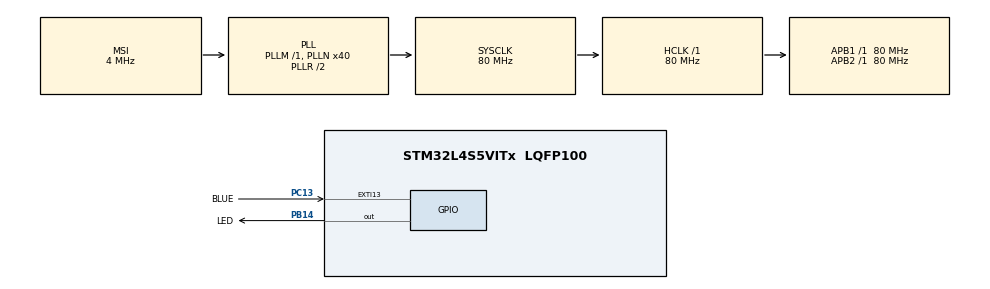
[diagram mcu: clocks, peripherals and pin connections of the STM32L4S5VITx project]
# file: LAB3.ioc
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ADC1.Channel-1\#ChannelRegularConversion=ADC_CHANNEL_TEMPSENSOR
ADC1.Channel-2\#ChannelRegularConversion=ADC_CHANNEL_VREFINT
ADC1.NbrOfConversion=2
ADC1.NbrOfConversionFlag=1
ADC1.OffsetNumber-1\#ChannelRegularConversion=ADC_OFFSET_NONE
ADC1.OffsetNumber-2\#ChannelRegularConversion=ADC_OFFSET_NONE
ADC1.Rank-1\#ChannelRegularConversion=1
ADC1.Rank-2\#ChannelRegularConversion=2
ADC1.Resolution=ADC_RESOLUTION_10B
ADC1.SamplingTime-1\#ChannelRegularConversion=ADC_SAMPLETIME_247CYCLES_5
ADC1.SamplingTime-2\#ChannelRegularConversion=ADC_SAMPLETIME_247CYCLES_5
ADC1.master=1
Dma.ADC1.0.Direction=DMA_PERIPH_TO_MEMORY
Dma.ADC1.0.EventEnable=DISABLE
Dma.ADC1.0.Instance=DMA1_Channel1
Dma.ADC1.0.MemDataAlignment=DMA_MDATAALIGN_HALFWORD
Dma.ADC1.0.MemInc=DMA_MINC_ENABLE
Dma.ADC1.0.Mode=DMA_NORMAL
Dma.ADC1.0.PeriphDataAlignment=DMA_PDATAALIGN_HALFWORD
Dma.ADC1.0.PeriphInc=DMA_PINC_DISABLE
Dma.ADC1.0.Polarity=HAL_DMAMUX_REQUEST_GEN_RISING
Dma.ADC1.0.Priority=DMA_PRIORITY_LOW
Dma.ADC1.0.RequestNumber=1
Dma.ADC1.0.SignalID=NONE
Dma.ADC1.0.SyncEnable=DISABLE
Dma.ADC1.0.SyncPolarity=HAL_DMAMUX_SYNC_NO_EVENT
Dma.ADC1.0.SyncRequestNumber=1
Dma.ADC1.0.SyncSignalID=NONE
Dma.Request0=ADC1
Mcu.Family=STM32L4
Mcu.Name=STM32L4S5VITx
Mcu.Package=LQFP100
NVIC.DMA1_Channel1_IRQn=true\:0\:0\:false\:false\:true\:false\:true\:true
NVIC.EXTI15_10_IRQn=true\:0\:0\:false\:false\:true\:true\:true\:true
NVIC.PriorityGroup=NVIC_PRIORITYGROUP_4
PA13\ (JTMS/SWDIO).Signal=SYS_JTMS-SWDIO
PB14.GPIO_Label=LED
PB14.Signal=GPIO_Output
PB3\ (JTDO/TRACESWO).Signal=SYS_JTDO-SWO
PC13.GPIO_Label=BLUE
PC13.Signal=GPXTI13
ProjectManager.HeapSize=0x200
ProjectManager.StackSize=0x400
ProjectManager.TargetToolchain=STM32CubeIDE
RCC.ADCFreq_Value=48000000
RCC.AHBFreq_Value=80000000
RCC.APB1Freq_Value=80000000
RCC.APB1TimFreq_Value=80000000
RCC.APB2Freq_Value=80000000
RCC.APB2TimFreq_Value=80000000
RCC.CortexFreq_Value=80000000
RCC.HCLKFreq_Value=80000000
RCC.HSE_VALUE=8000000
RCC.HSI48_VALUE=48000000
RCC.HSI_VALUE=16000000
RCC.LSE_VALUE=32768
RCC.MSI_VALUE=4000000
RCC.PLLN=40
RCC.PLLSAI1N=24
RCC.SYSCLKFreq_VALUE=80000000
RCC.SYSCLKSource=RCC_SYSCLKSOURCE_PLLCLK
RCC.USBFreq_Value=48000000
RCC.VCOOutputFreq_Value=160000000
VP_ADC1_TempSens_Input.Mode=IN-TempSens
VP_ADC1_Vref_Input.Mode=IN-Vrefint
board=B-L4S5I-IOT01A

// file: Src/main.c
/* USER CODE BEGIN Header */
/**
  ******************************************************************************
  * @file           : main.c
  * @brief          : Main program body
  ******************************************************************************
  * @attention
  *
  * Copyright (c) 2022 STMicroelectronics.
  * All rights reserved.
  *
  * This software is licensed under terms that can be found in the LICENSE file
  * in the root directory of this software component.
  * If no LICENSE file comes with this software, it is provided AS-IS.
  *
  ******************************************************************************
  */
/* USER CODE END Header */
#include "main.h"

/* USER CODE BEGIN PD */
//((uint16_t*)((uint32_t)0x1FFF75CA))
#define TS_CAL1_ADD ((uint16_t*)((uint32_t)0x1FFF75A8)) // 30
#define TS_CAL2_ADD ((uint16_t*)((uint32_t)0x1FFF75CA)) // 110
/* USER CODE END PD */

ADC_HandleTypeDef hadc1;
DMA_HandleTypeDef hdma_adc1;

void SystemClock_Config(void);
static void MX_DMA_Init(void);
static void MX_GPIO_Init(void);
static void MX_ADC1_Init(void);

/* USER CODE BEGIN 0 */

uint16_t data[2];

/* USER CODE END 0 */

int main(void)
{

  /* MCU Configuration--------------------------------------------------------*/

  /* Reset of all peripherals, Initializes the Flash interface and the Systick. */
  HAL_Init();

  /* Configure the system clock */
  SystemClock_Config();

  /* Initialize all configured peripherals */
  MX_DMA_Init();
  MX_GPIO_Init();
  MX_ADC1_Init();
  /* USER CODE BEGIN 2 */

  data[0] = 0;
  data[1] = 0;
  //temperature = 0;

  /* USER CODE END 2 */

  /* Infinite loop */
  while (1)
  {
	  //HAL_Delay(100);
	  //HAL_ADC_Start_DMA(&hadc1, &data, 2);

  }
}

void SystemClock_Config(void)
{
  RCC_OscInitTypeDef RCC_OscInitStruct = {0};
  RCC_ClkInitTypeDef RCC_ClkInitStruct = {0};

  /** Configure the main internal regulator output voltage
  */
  if (HAL_PWREx_ControlVoltageScaling(PWR_REGULATOR_VOLTAGE_SCALE1) != HAL_OK)
  {
    Error_Handler();
  }

  /** Initializes the RCC Oscillators according to the specified parameters
  * in the RCC_OscInitTypeDef structure.
  */
  RCC_OscInitStruct.OscillatorType = RCC_OSCILLATORTYPE_MSI;
  RCC_OscInitStruct.MSIState = RCC_MSI_ON;
  RCC_OscInitStruct.MSICalibrationValue = 0;
  RCC_OscInitStruct.MSIClockRange = RCC_MSIRANGE_6;
  RCC_OscInitStruct.PLL.PLLState = RCC_PLL_ON;
  RCC_OscInitStruct.PLL.PLLSource = RCC_PLLSOURCE_MSI;
  RCC_OscInitStruct.PLL.PLLM = 1;
  RCC_OscInitStruct.PLL.PLLN = 40;
  RCC_OscInitStruct.PLL.PLLP = RCC_PLLP_DIV2;
  RCC_OscInitStruct.PLL.PLLQ = RCC_PLLQ_DIV2;
  RCC_OscInitStruct.PLL.PLLR = RCC_PLLR_DIV2;
  if (HAL_RCC_OscConfig(&RCC_OscInitStruct) != HAL_OK)
  {
    Error_Handler();
  }

  /** Initializes the CPU, AHB and APB buses clocks
  */
  RCC_ClkInitStruct.ClockType = RCC_CLOCKTYPE_HCLK|RCC_CLOCKTYPE_SYSCLK
                              |RCC_CLOCKTYPE_PCLK1|RCC_CLOCKTYPE_PCLK2;
  RCC_ClkInitStruct.SYSCLKSource = RCC_SYSCLKSOURCE_PLLCLK;
  RCC_ClkInitStruct.AHBCLKDivider = RCC_SYSCLK_DIV1;
  RCC_ClkInitStruct.APB1CLKDivider = RCC_HCLK_DIV1;
  RCC_ClkInitStruct.APB2CLKDivider = RCC_HCLK_DIV1;

  if (HAL_RCC_ClockConfig(&RCC_ClkInitStruct, FLASH_LATENCY_3) != HAL_OK)
  {
    Error_Handler();
  }
}

static void MX_ADC1_Init(void)
{

  ADC_ChannelConfTypeDef sConfig = {0};

  /** Common config
  */
  hadc1.Instance = ADC1;
  hadc1.Init.ClockPrescaler = ADC_CLOCK_ASYNC_DIV1;
  hadc1.Init.Resolution = ADC_RESOLUTION_10B;
  hadc1.Init.DataAlign = ADC_DATAALIGN_RIGHT;
  hadc1.Init.ScanConvMode = ADC_SCAN_ENABLE;
  hadc1.Init.EOCSelection = ADC_EOC_SINGLE_CONV;
  hadc1.Init.LowPowerAutoWait = DISABLE;
  hadc1.Init.ContinuousConvMode = DISABLE;
  hadc1.Init.NbrOfConversion = 2;
  hadc1.Init.DiscontinuousConvMode = DISABLE;
  hadc1.Init.ExternalTrigConv = ADC_SOFTWARE_START;
  hadc1.Init.ExternalTrigConvEdge = ADC_EXTERNALTRIGCONVEDGE_NONE;
  hadc1.Init.DMAContinuousRequests = DISABLE;
  hadc1.Init.Overrun = ADC_OVR_DATA_PRESERVED;
  hadc1.Init.OversamplingMode = DISABLE;
  if (HAL_ADC_Init(&hadc1) != HAL_OK)
  {
    Error_Handler();
  }

  /** Configure Regular Channel
  */
  sConfig.Channel = ADC_CHANNEL_TEMPSENSOR;
  sConfig.Rank = ADC_REGULAR_RANK_1;
  sConfig.SamplingTime = ADC_SAMPLETIME_247CYCLES_5;
  sConfig.SingleDiff = ADC_SINGLE_ENDED;
  sConfig.OffsetNumber = ADC_OFFSET_NONE;
  sConfig.Offset = 0;
  if (HAL_ADC_ConfigChannel(&hadc1, &sConfig) != HAL_OK)
  {
    Error_Handler();
  }

  /** Configure Regular Channel
  */
  sConfig.Channel = ADC_CHANNEL_VREFINT;
  sConfig.Rank = ADC_REGULAR_RANK_2;
  if (HAL_ADC_ConfigChannel(&hadc1, &sConfig) != HAL_OK)
  {
    Error_Handler();
  }

}

static void MX_DMA_Init(void)
{

  /* DMA controller clock enable */
  __HAL_RCC_DMAMUX1_CLK_ENABLE();
  __HAL_RCC_DMA1_CLK_ENABLE();

  /* DMA interrupt init */
  /* DMA1_Channel1_IRQn interrupt configuration */
  HAL_NVIC_SetPriority(DMA1_Channel1_IRQn, 0, 0);
  HAL_NVIC_EnableIRQ(DMA1_Channel1_IRQn);

}

static void MX_GPIO_Init(void)
{
  GPIO_InitTypeDef GPIO_InitStruct = {0};

  /* GPIO Ports Clock Enable */
  __HAL_RCC_GPIOC_CLK_ENABLE();
  __HAL_RCC_GPIOB_CLK_ENABLE();
  __HAL_RCC_GPIOA_CLK_ENABLE();

  /*Configure GPIO pin Output Level */
  HAL_GPIO_WritePin(LED_GPIO_Port, LED_Pin, GPIO_PIN_RESET);

  /*Configure GPIO pin : BLUE_Pin */
  GPIO_InitStruct.Pin = BLUE_Pin;
  GPIO_InitStruct.Mode = GPIO_MODE_IT_RISING;
  GPIO_InitStruct.Pull = GPIO_NOPULL;
  HAL_GPIO_Init(BLUE_GPIO_Port, &GPIO_InitStruct);

  /*Configure GPIO pin : LED_Pin */
  GPIO_InitStruct.Pin = LED_Pin;
  GPIO_InitStruct.Mode = GPIO_MODE_OUTPUT_PP;
  GPIO_InitStruct.Pull = GPIO_NOPULL;
  GPIO_InitStruct.Speed = GPIO_SPEED_FREQ_LOW;
  HAL_GPIO_Init(LED_GPIO_Port, &GPIO_InitStruct);

  /* EXTI interrupt init*/
  HAL_NVIC_SetPriority(EXTI15_10_IRQn, 0, 0);
  HAL_NVIC_EnableIRQ(EXTI15_10_IRQn);

}

/* USER CODE BEGIN 4 */

void HAL_GPIO_EXTI_Callback (uint16_t GPIO_Pin) {

//	HAL_ADC_Start(&hadc1);
//	int32_t sensorValue = 0;
//	float temperature = 0;
//	if(HAL_ADC_PollForConversion(&hadc1, 100) == HAL_OK) {
//		HAL_ADC_Stop(&hadc1);
//		//HAL_ADC_Start(&hadc1);
//	    sensorValue = HAL_ADC_GetValue(&hadc1);
//
//	    //float step1 = ((80) / (((float)(*TEMPSENSOR_CAL2_ADDR) - (float)(*TEMPSENSOR_CAL1_ADDR)));
//	    //float step2 = sensorValue - (float)(*TEMPSENSOR_CAL1_ADDR);
//	    //temperature = (step1 * step2) + 30.0f;
//
//
//	    temperature =((((float)(sensorValue/(float)TEMPSENSOR_CAL_VREFANALOG) - 30) * (float)((float)TEMPSENSOR_CAL2_TEMP - (float)TEMPSENSOR_CAL1_TEMP)) / (float)((float)*TEMPSENSOR_CAL2_ADDR - (float)*TEMPSENSOR_CAL1_ADDR) + 30);
//	    int debug = 0;
//

	// 	temperature = ((((float)((float)data[0]/(float)TEMPSENSOR_CAL_VREFANALOG) - 30) * (float)((float)TEMPSENSOR_CAL2_TEMP - (float)TEMPSENSOR_CAL1_TEMP)) / (float)((float)*TEMPSENSOR_CAL2_ADDR - (float)*TEMPSENSOR_CAL1_ADDR) + 30);
//	}

	HAL_ADC_Start_DMA(&hadc1, &data, 2);

	if(HAL_GPIO_ReadPin(GPIOB, LED_Pin) == GPIO_PIN_SET) {
		HAL_GPIO_WritePin(GPIOB, LED_Pin, GPIO_PIN_RESET);
	} else {
		HAL_GPIO_WritePin(GPIOB, LED_Pin, GPIO_PIN_SET);
	}
}

void HAL_ADC_ConvCpltCallback (ADC_HandleTypeDef * hadc){
	HAL_ADC_Stop_DMA (&hadc1);
	uint16_t zero = data[0];
	uint16_t one = data[1];

	float vdd = 3.0 * ((float)TEMPSENSOR_CAL_VREFANALOG /(float)one);
	vdd = vdd / 3.0;
	float temperature = 0;
	temperature = ((((float)((zero*vdd)/1023) - TEMPSENSOR_CAL1_TEMP) * (float)((float)TEMPSENSOR_CAL2_TEMP - (float)TEMPSENSOR_CAL1_TEMP)) / (float)((float)*TEMPSENSOR_CAL2_ADDR - (float)*TEMPSENSOR_CAL1_ADDR) + TEMPSENSOR_CAL1_TEMP);
	//temperature = __HAL_ADC_CALC_TEMPERATURE((uint16_t)((zero*vdd)/4095), (uint16_t)vdd, ADC_RESOLUTION_12B);
	int x = 3;

// 1023 & 4095

}

/* USER CODE END 4 */

void Error_Handler(void)
{
  __disable_irq();
  while (1)
  {
  }
}
